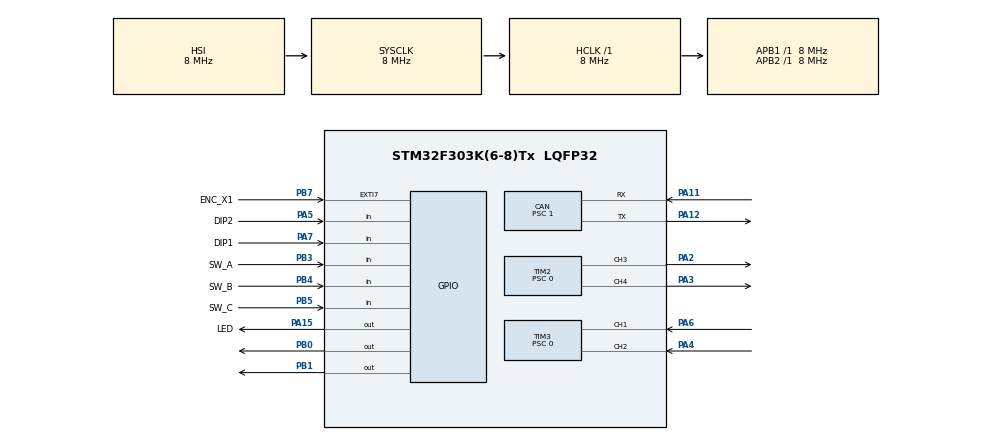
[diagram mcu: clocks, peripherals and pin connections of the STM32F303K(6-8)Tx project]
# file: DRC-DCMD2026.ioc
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CAN.ABOM=ENABLE
CAN.BS1=CAN_BS1_5TQ
CAN.BS2=CAN_BS2_2TQ
CAN.CalculateBaudRate=1000000
CAN.CalculateTimeBit=1000
CAN.CalculateTimeQuantum=125.0
CAN.Prescaler=1
CAN.SJW=CAN_SJW_2TQ
Mcu.Family=STM32F3
Mcu.Name=STM32F303K(6-8)Tx
Mcu.Package=LQFP32
NVIC.EXTI9_5_IRQn=true\:0\:0\:false\:false\:true\:true\:true\:true
NVIC.PriorityGroup=NVIC_PRIORITYGROUP_4
PA11.Mode=CAN_Activate
PA11.Signal=CAN_RX
PA12.Mode=CAN_Activate
PA12.Signal=CAN_TX
PA13.Mode=Serial_Wire
PA13.Signal=SYS_JTMS-SWDIO
PA14.Mode=Serial_Wire
PA14.Signal=SYS_JTCK-SWCLK
PA2.Signal=S_TIM2_CH3
PA3.Signal=S_TIM2_CH4
PA4.GPIO_PuPd=GPIO_NOPULL
PA4.Signal=S_TIM3_CH2
PA5.GPIO_Label=DIP2
PA5.GPIO_PuPd=GPIO_PULLUP
PA5.Signal=GPIO_Input
PA6.GPIO_PuPd=GPIO_NOPULL
PA6.Signal=S_TIM3_CH1
PA7.GPIO_Label=DIP1
PA7.GPIO_PuPd=GPIO_PULLUP
PA7.Signal=GPIO_Input
PB0.PinState=GPIO_PIN_SET
PB0.Signal=GPIO_Output
PB1.PinState=GPIO_PIN_SET
PB1.Signal=GPIO_Output
PA15.GPIO_Label=LED
PA15.Signal=GPIO_Output
PB3.GPIO_Label=SW_A
PB3.GPIO_PuPd=GPIO_PULLUP
PB3.Signal=GPIO_Input
PB4.GPIO_Label=SW_B
PB4.GPIO_PuPd=GPIO_PULLUP
PB4.Signal=GPIO_Input
PB5.GPIO_Label=SW_C
PB5.GPIO_PuPd=GPIO_PULLUP
PB5.Signal=GPIO_Input
PB7.GPIO_Label=ENC_X1
PB7.GPIO_ModeDefaultEXTI=GPIO_MODE_IT_RISING
PB7.GPIO_PuPd=GPIO_NOPULL
PB7.Signal=GPXTI7
ProjectManager.HeapSize=0x200
ProjectManager.StackSize=0x400
ProjectManager.TargetToolchain=CMake
RCC.AHBFreq_Value=8000000
RCC.APB1Freq_Value=8000000
RCC.APB2Freq_Value=8000000
RCC.CortexFreq_Value=8000000
RCC.HSE_VALUE=8000000
RCC.HSI_VALUE=8000000
RCC.SYSCLKFreq_VALUE=8000000
SH.S_TIM2_CH3.0=TIM2_CH3,PWM Generation3 CH3
SH.S_TIM2_CH4.0=TIM2_CH4,PWM Generation4 CH4
SH.S_TIM3_CH1.0=TIM3_CH1,Encoder_Interface
SH.S_TIM3_CH2.0=TIM3_CH2,Encoder_Interface
TIM2.Channel-PWM\ Generation3\ CH3=TIM_CHANNEL_3
TIM2.Channel-PWM\ Generation4\ CH4=TIM_CHANNEL_4
TIM2.OCPolarity_3=TIM_OCPOLARITY_LOW
TIM2.OCPolarity_4=TIM_OCPOLARITY_LOW
TIM2.Period=399
TIM2.Prescaler=0
TIM2.Pulse-PWM\ Generation3\ CH3=0
TIM2.Pulse-PWM\ Generation4\ CH4=0
TIM3.EncoderMode=TIM_ENCODERMODE_TI12
TIM3.IC1Filter=0
TIM3.IC1Polarity=TIM_ICPOLARITY_RISING
TIM3.IC1Prescaler=TIM_ICPSC_DIV1
TIM3.IC1Selection=TIM_ICSELECTION_DIRECTTI
TIM3.IC2Filter=0
TIM3.IC2Polarity=TIM_ICPOLARITY_RISING
TIM3.IC2Prescaler=TIM_ICPSC_DIV1
TIM3.IC2Selection=TIM_ICSELECTION_DIRECTTI
TIM3.Period=65535
TIM3.Prescaler=0
VP_TIM2_VS_ClockSourceINT.Mode=Internal
board=custom

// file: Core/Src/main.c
/* USER CODE BEGIN Header */
/**
  ******************************************************************************
  * @file           : main.c
  * @brief          : Main program body
  ******************************************************************************
  * @attention
  *
  * Copyright (c) 2026 STMicroelectronics.
  * All rights reserved.
  *
  * This software is licensed under terms that can be found in the LICENSE file
  * in the root directory of this software component.
  * If no LICENSE file comes with this software, it is provided AS-IS.
  *
  ******************************************************************************
  */
/* USER CODE END Header */
#include "main.h"

/* USER CODE BEGIN Includes */
#include "app.h"

/* USER CODE END Includes */

CAN_HandleTypeDef hcan;

TIM_HandleTypeDef htim2;
TIM_HandleTypeDef htim3;

void SystemClock_Config(void);
static void MX_GPIO_Init(void);
static void MX_TIM2_Init(void);
static void MX_CAN_Init(void);
static void MX_TIM3_Init(void);

int main(void)
{

  /* MCU Configuration--------------------------------------------------------*/

  /* Reset of all peripherals, Initializes the Flash interface and the Systick. */
  HAL_Init();

  /* Configure the system clock */
  SystemClock_Config();

  /* USER CODE BEGIN SysInit */
  dcmd_brake();

  /* USER CODE END SysInit */

  /* Initialize all configured peripherals */
  MX_GPIO_Init();
  MX_TIM2_Init();
  MX_CAN_Init();
  MX_TIM3_Init();
  /* USER CODE BEGIN 2 */
  setup();

  /* USER CODE END 2 */

  /* Infinite loop */
  while (1)
  {

    /* USER CODE BEGIN 3 */
    loop();
  }
  /* USER CODE END 3 */
}

void SystemClock_Config(void)
{
  RCC_OscInitTypeDef RCC_OscInitStruct = {0};
  RCC_ClkInitTypeDef RCC_ClkInitStruct = {0};

  /** Initializes the RCC Oscillators according to the specified parameters
  * in the RCC_OscInitTypeDef structure.
  */
  RCC_OscInitStruct.OscillatorType = RCC_OSCILLATORTYPE_HSI;
  RCC_OscInitStruct.HSIState = RCC_HSI_ON;
  RCC_OscInitStruct.HSICalibrationValue = RCC_HSICALIBRATION_DEFAULT;
  RCC_OscInitStruct.PLL.PLLState = RCC_PLL_NONE;
  if (HAL_RCC_OscConfig(&RCC_OscInitStruct) != HAL_OK)
  {
    Error_Handler();
  }

  /** Initializes the CPU, AHB and APB buses clocks
  */
  RCC_ClkInitStruct.ClockType = RCC_CLOCKTYPE_HCLK|RCC_CLOCKTYPE_SYSCLK
                              |RCC_CLOCKTYPE_PCLK1|RCC_CLOCKTYPE_PCLK2;
  RCC_ClkInitStruct.SYSCLKSource = RCC_SYSCLKSOURCE_HSI;
  RCC_ClkInitStruct.AHBCLKDivider = RCC_SYSCLK_DIV1;
  RCC_ClkInitStruct.APB1CLKDivider = RCC_HCLK_DIV1;
  RCC_ClkInitStruct.APB2CLKDivider = RCC_HCLK_DIV1;

  if (HAL_RCC_ClockConfig(&RCC_ClkInitStruct, FLASH_LATENCY_0) != HAL_OK)
  {
    Error_Handler();
  }
}

static void MX_CAN_Init(void)
{

  hcan.Instance = CAN;
  hcan.Init.Prescaler = 1;
  hcan.Init.Mode = CAN_MODE_NORMAL;
  hcan.Init.SyncJumpWidth = CAN_SJW_2TQ;
  hcan.Init.TimeSeg1 = CAN_BS1_5TQ;
  hcan.Init.TimeSeg2 = CAN_BS2_2TQ;
  hcan.Init.TimeTriggeredMode = DISABLE;
  hcan.Init.AutoBusOff = ENABLE;
  hcan.Init.AutoWakeUp = DISABLE;
  hcan.Init.AutoRetransmission = DISABLE;
  hcan.Init.ReceiveFifoLocked = DISABLE;
  hcan.Init.TransmitFifoPriority = DISABLE;
  if (HAL_CAN_Init(&hcan) != HAL_OK)
  {
    Error_Handler();
  }

}

static void MX_TIM2_Init(void)
{

  TIM_ClockConfigTypeDef sClockSourceConfig = {0};
  TIM_MasterConfigTypeDef sMasterConfig = {0};
  TIM_OC_InitTypeDef sConfigOC = {0};

  htim2.Instance = TIM2;
  htim2.Init.Prescaler = 0;
  htim2.Init.CounterMode = TIM_COUNTERMODE_UP;
  htim2.Init.Period = 399;
  htim2.Init.ClockDivision = TIM_CLOCKDIVISION_DIV1;
  htim2.Init.AutoReloadPreload = TIM_AUTORELOAD_PRELOAD_DISABLE;
  if (HAL_TIM_Base_Init(&htim2) != HAL_OK)
  {
    Error_Handler();
  }
  sClockSourceConfig.ClockSource = TIM_CLOCKSOURCE_INTERNAL;
  if (HAL_TIM_ConfigClockSource(&htim2, &sClockSourceConfig) != HAL_OK)
  {
    Error_Handler();
  }
  if (HAL_TIM_PWM_Init(&htim2) != HAL_OK)
  {
    Error_Handler();
  }
  sMasterConfig.MasterOutputTrigger = TIM_TRGO_RESET;
  sMasterConfig.MasterSlaveMode = TIM_MASTERSLAVEMODE_DISABLE;
  if (HAL_TIMEx_MasterConfigSynchronization(&htim2, &sMasterConfig) != HAL_OK)
  {
    Error_Handler();
  }
  sConfigOC.OCMode = TIM_OCMODE_PWM1;
  sConfigOC.Pulse = 0;
  sConfigOC.OCPolarity = TIM_OCPOLARITY_LOW;
  sConfigOC.OCFastMode = TIM_OCFAST_DISABLE;
  if (HAL_TIM_PWM_ConfigChannel(&htim2, &sConfigOC, TIM_CHANNEL_3) != HAL_OK)
  {
    Error_Handler();
  }
  if (HAL_TIM_PWM_ConfigChannel(&htim2, &sConfigOC, TIM_CHANNEL_4) != HAL_OK)
  {
    Error_Handler();
  }
  HAL_TIM_MspPostInit(&htim2);

}

static void MX_TIM3_Init(void)
{

  TIM_Encoder_InitTypeDef sConfig = {0};
  TIM_MasterConfigTypeDef sMasterConfig = {0};

  htim3.Instance = TIM3;
  htim3.Init.Prescaler = 0;
  htim3.Init.CounterMode = TIM_COUNTERMODE_UP;
  htim3.Init.Period = 65535;
  htim3.Init.ClockDivision = TIM_CLOCKDIVISION_DIV1;
  htim3.Init.AutoReloadPreload = TIM_AUTORELOAD_PRELOAD_DISABLE;
  sConfig.EncoderMode = TIM_ENCODERMODE_TI12;
  sConfig.IC1Polarity = TIM_ICPOLARITY_RISING;
  sConfig.IC1Selection = TIM_ICSELECTION_DIRECTTI;
  sConfig.IC1Prescaler = TIM_ICPSC_DIV1;
  sConfig.IC1Filter = 0;
  sConfig.IC2Polarity = TIM_ICPOLARITY_RISING;
  sConfig.IC2Selection = TIM_ICSELECTION_DIRECTTI;
  sConfig.IC2Prescaler = TIM_ICPSC_DIV1;
  sConfig.IC2Filter = 0;
  if (HAL_TIM_Encoder_Init(&htim3, &sConfig) != HAL_OK)
  {
    Error_Handler();
  }
  sMasterConfig.MasterOutputTrigger = TIM_TRGO_RESET;
  sMasterConfig.MasterSlaveMode = TIM_MASTERSLAVEMODE_DISABLE;
  if (HAL_TIMEx_MasterConfigSynchronization(&htim3, &sMasterConfig) != HAL_OK)
  {
    Error_Handler();
  }

}

static void MX_GPIO_Init(void)
{
  GPIO_InitTypeDef GPIO_InitStruct = {0};

  /* GPIO Ports Clock Enable */
  __HAL_RCC_GPIOA_CLK_ENABLE();
  __HAL_RCC_GPIOB_CLK_ENABLE();

  /*Configure GPIO pin Output Level */
  HAL_GPIO_WritePin(GPIOB, GPIO_PIN_0|GPIO_PIN_1, GPIO_PIN_SET);

  /*Configure GPIO pin Output Level */
  HAL_GPIO_WritePin(LED_GPIO_Port, LED_Pin, GPIO_PIN_RESET);

  /*Configure GPIO pin : LED_Pin */
  GPIO_InitStruct.Pin = LED_Pin;
  GPIO_InitStruct.Mode = GPIO_MODE_OUTPUT_PP;
  GPIO_InitStruct.Pull = GPIO_NOPULL;
  GPIO_InitStruct.Speed = GPIO_SPEED_FREQ_LOW;
  HAL_GPIO_Init(LED_GPIO_Port, &GPIO_InitStruct);

  /*Configure GPIO pins : DIP2_Pin DIP1_Pin */
  GPIO_InitStruct.Pin = DIP2_Pin|DIP1_Pin;
  GPIO_InitStruct.Mode = GPIO_MODE_INPUT;
  GPIO_InitStruct.Pull = GPIO_PULLUP;
  HAL_GPIO_Init(GPIOA, &GPIO_InitStruct);

  /*Configure GPIO pins : PB0 PB1 */
  GPIO_InitStruct.Pin = GPIO_PIN_0|GPIO_PIN_1;
  GPIO_InitStruct.Mode = GPIO_MODE_OUTPUT_PP;
  GPIO_InitStruct.Pull = GPIO_NOPULL;
  GPIO_InitStruct.Speed = GPIO_SPEED_FREQ_LOW;
  HAL_GPIO_Init(GPIOB, &GPIO_InitStruct);

  /*Configure GPIO pins : SW_A_Pin SW_B_Pin SW_C_Pin */
  GPIO_InitStruct.Pin = SW_A_Pin|SW_B_Pin|SW_C_Pin;
  GPIO_InitStruct.Mode = GPIO_MODE_INPUT;
  GPIO_InitStruct.Pull = GPIO_PULLUP;
  HAL_GPIO_Init(GPIOB, &GPIO_InitStruct);

  /*Configure GPIO pin : ENC_X1_Pin */
  GPIO_InitStruct.Pin = ENC_X1_Pin;
  GPIO_InitStruct.Mode = GPIO_MODE_IT_RISING;
  GPIO_InitStruct.Pull = GPIO_NOPULL;
  HAL_GPIO_Init(ENC_X1_GPIO_Port, &GPIO_InitStruct);

  /* EXTI interrupt init*/
  HAL_NVIC_SetPriority(EXTI9_5_IRQn, 0, 0);
  HAL_NVIC_EnableIRQ(EXTI9_5_IRQn);

}

void Error_Handler(void)
{
  /* USER CODE BEGIN Error_Handler_Debug */
  dcmd_brake();
  /* User can add his own implementation to report the HAL error return state */
  __disable_irq();
  while (1)
  {
  }
  /* USER CODE END Error_Handler_Debug */
}
